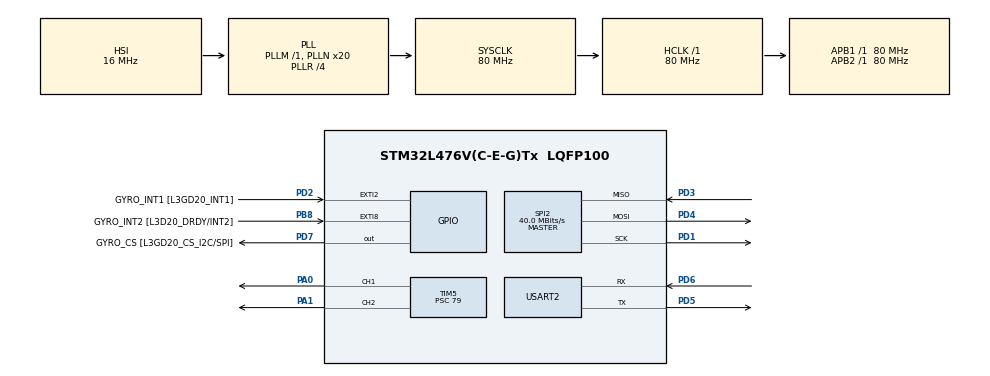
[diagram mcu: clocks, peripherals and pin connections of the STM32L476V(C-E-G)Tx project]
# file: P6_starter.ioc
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FREERTOS.Tasks01=defaultTask,0,128,StartDefaultTask,Default,NULL
FREERTOS.configTOTAL_HEAP_SIZE=10000
FREERTOS.configUSE_IDLE_HOOK=1
Mcu.Family=STM32L4
Mcu.Name=STM32L476V(C-E-G)Tx
Mcu.Package=LQFP100
NVIC.PriorityGroup=NVIC_PRIORITYGROUP_4
NVIC.TIM2_IRQn=true\:0\:0\:false\:false\:true\:false\:false
NVIC.TimeBase=TIM2_IRQn
NVIC.TimeBaseIP=TIM2
NVIC.USART2_IRQn=true\:5\:0\:false\:false\:true\:true\:true
PA0.GPIO_Speed=GPIO_SPEED_FREQ_HIGH
PA0.Signal=S_TIM5_CH1
PA1.GPIO_Speed=GPIO_SPEED_FREQ_HIGH
PA1.Signal=S_TIM5_CH2
PB8.GPIO_Label=GYRO_INT2 [L3D20_DRDY/INT2]
PB8.Signal=GPXTI8
PD1.Mode=Full_Duplex_Master
PD1.Signal=SPI2_SCK
PD2.GPIO_Label=GYRO_INT1 [L3GD20_INT1]
PD2.Signal=GPXTI2
PD3.Mode=Full_Duplex_Master
PD3.Signal=SPI2_MISO
PD4.Mode=Full_Duplex_Master
PD4.Signal=SPI2_MOSI
PD5.Mode=Asynchronous
PD5.Signal=USART2_TX
PD6.Mode=Asynchronous
PD6.Signal=USART2_RX
PD7.GPIO_Label=GYRO_CS [L3GD20_CS_I2C/SPI]
PD7.GPIO_Speed=GPIO_SPEED_FREQ_VERY_HIGH
PD7.Signal=GPIO_Output
ProjectManager.HeapSize=0x200
ProjectManager.StackSize=0x400
ProjectManager.TargetToolchain=MDK-ARM V5
RCC.ADCFreq_Value=96000000
RCC.AHBFreq_Value=80000000
RCC.APB1Freq_Value=80000000
RCC.APB1TimFreq_Value=80000000
RCC.APB2Freq_Value=80000000
RCC.APB2TimFreq_Value=80000000
RCC.CortexFreq_Value=80000000
RCC.HCLKFreq_Value=80000000
RCC.HSE_VALUE=8000000
RCC.HSI_VALUE=16000000
RCC.LSE_VALUE=32768
RCC.MSI_VALUE=4000000
RCC.PLLN=20
RCC.PLLR=RCC_PLLR_DIV4
RCC.PLLSAI1N=12
RCC.PLLSAI1Q=RCC_PLLQ_DIV4
RCC.PLLSourceVirtual=RCC_PLLSOURCE_HSI
RCC.SYSCLKFreq_VALUE=80000000
RCC.SYSCLKSource=RCC_SYSCLKSOURCE_PLLCLK
RCC.USBFreq_Value=48000000
RCC.VCOOutputFreq_Value=320000000
SH.S_TIM5_CH1.0=TIM5_CH1,PWM Generation1 CH1
SH.S_TIM5_CH2.0=TIM5_CH2,PWM Generation2 CH2
SPI2.CalculateBaudRate=40.0 MBits/s
SPI2.Direction=SPI_DIRECTION_2LINES
SPI2.Mode=SPI_MODE_MASTER
SPI2.VirtualType=VM_MASTER
TIM5.Channel-PWM\ Generation1\ CH1=TIM_CHANNEL_1
TIM5.Channel-PWM\ Generation2\ CH2=TIM_CHANNEL_2
TIM5.Period=20000
TIM5.Prescaler=79
TIM5.Pulse-PWM\ Generation1\ CH1=10000
TIM5.Pulse-PWM\ Generation2\ CH2=1000
USART2.VirtualMode-Asynchronous=VM_ASYNC
VP_FREERTOS_VS_ENABLE.Mode=Enabled
VP_RNG_VS_RNG.Mode=RNG_Activate
VP_SYS_VS_tim2.Mode=TIM2
VP_TIM5_VS_ClockSourceINT.Mode=Internal
board=custom

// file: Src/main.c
/* USER CODE BEGIN Header */
/**
  ******************************************************************************
  * @file           : main.c
  * @brief          : Main program body
  ******************************************************************************
  * This notice applies to any and all portions of this file
  * that are not between comment pairs USER CODE BEGIN and
  * USER CODE END. Other portions of this file, whether
  * inserted by the user or by software development tools
  * are owned by their respective copyright owners.
  *
  * Copyright (c) 2019 STMicroelectronics International N.V.
  * All rights reserved.
  *
  * Redistribution and use in source and binary forms, with or without
  * modification, are permitted, provided that the following conditions are met:
  *
  * 1. Redistribution of source code must retain the above copyright notice,
  *    this list of conditions and the following disclaimer.
  * 2. Redistributions in binary form must reproduce the above copyright notice,
  *    this list of conditions and the following disclaimer in the documentation
  *    and/or other materials provided with the distribution.
  * 3. Neither the name of STMicroelectronics nor the names of other
  *    contributors to this software may be used to endorse or promote products
  *    derived from this software without specific written permission.
  * 4. This software, including modifications and/or derivative works of this
  *    software, must execute solely and exclusively on microcontroller or
  *    microprocessor devices manufactured by or for STMicroelectronics.
  * 5. Redistribution and use of this software other than as permitted under
  *    this license is void and will automatically terminate your rights under
  *    this license.
  *
  * THIS SOFTWARE IS PROVIDED BY STMICROELECTRONICS AND CONTRIBUTORS "AS IS"
  * AND ANY EXPRESS, IMPLIED OR STATUTORY WARRANTIES, INCLUDING, BUT NOT
  * LIMITED TO, THE IMPLIED WARRANTIES OF MERCHANTABILITY, FITNESS FOR A
  * PARTICULAR PURPOSE AND NON-INFRINGEMENT OF THIRD PARTY INTELLECTUAL PROPERTY
  * RIGHTS ARE DISCLAIMED TO THE FULLEST EXTENT PERMITTED BY LAW. IN NO EVENT
  * SHALL STMICROELECTRONICS OR CONTRIBUTORS BE LIABLE FOR ANY DIRECT, INDIRECT,
  * INCIDENTAL, SPECIAL, EXEMPLARY, OR CONSEQUENTIAL DAMAGES (INCLUDING, BUT NOT
  * LIMITED TO, PROCUREMENT OF SUBSTITUTE GOODS OR SERVICES; LOSS OF USE, DATA,
  * OR PROFITS; OR BUSINESS INTERRUPTION) HOWEVER CAUSED AND ON ANY THEORY OF
  * LIABILITY, WHETHER IN CONTRACT, STRICT LIABILITY, OR TORT (INCLUDING
  * NEGLIGENCE OR OTHERWISE) ARISING IN ANY WAY OUT OF THE USE OF THIS SOFTWARE,
  * EVEN IF ADVISED OF THE POSSIBILITY OF SUCH DAMAGE.
  *
  ******************************************************************************
  */
/* USER CODE END Header */

#include "main.h"
#include "cmsis_os.h"
#include "rng.h"
#include "spi.h"
#include "tim.h"
#include "usart.h"
#include "gpio.h"
#include "servo.h"
#include "Timer.h"
#include "GPIOINP.h"

/* USER CODE BEGIN Includes */
#include "stdio.h"
#include "string.h"
/* USER CODE END Includes */

void SystemClock_Config(void);
void MX_FREERTOS_Init(void);

int main(void)
{

  /* MCU Configuration--------------------------------------------------------*/

  /* Reset of all peripherals, Initializes the Flash interface and the Systick. */
  HAL_Init();

  /* Configure the system clock */
  SystemClock_Config();

  /* Initialize all configured peripherals */
  MX_GPIO_Init();
  MX_USART2_UART_Init();
  MX_RNG_Init();
  MX_TIM5_Init();
  MX_SPI2_Init();
  initTIM2();
  initTIM3();
  initGPIOA();

  /* USER CODE BEGIN 2 */

  gyro_task_init();
  servo_task_init(0, "SERVO_TASK");
  player_servo_task_init(1, "PLAYER_SERVO_TASK");

  /* USER CODE END 2 */

  /* Call init function for freertos objects (in freertos.c) */
  MX_FREERTOS_Init();

  /* Start scheduler */
  osKernelStart();

  /* We should never get here as control is now taken by the scheduler */

  /* Infinite loop */
  while (1)
  {

  }
}

void SystemClock_Config(void)
{
  RCC_OscInitTypeDef RCC_OscInitStruct = {0};
  RCC_ClkInitTypeDef RCC_ClkInitStruct = {0};
  RCC_PeriphCLKInitTypeDef PeriphClkInit = {0};

  /**Initializes the CPU, AHB and APB busses clocks
  */
  RCC_OscInitStruct.OscillatorType = RCC_OSCILLATORTYPE_HSI;
  RCC_OscInitStruct.HSIState = RCC_HSI_ON;
  RCC_OscInitStruct.HSICalibrationValue = RCC_HSICALIBRATION_DEFAULT;
  RCC_OscInitStruct.PLL.PLLState = RCC_PLL_ON;
  RCC_OscInitStruct.PLL.PLLSource = RCC_PLLSOURCE_HSI;
  RCC_OscInitStruct.PLL.PLLM = 1;
  RCC_OscInitStruct.PLL.PLLN = 20;
  RCC_OscInitStruct.PLL.PLLP = RCC_PLLP_DIV7;
  RCC_OscInitStruct.PLL.PLLQ = RCC_PLLQ_DIV2;
  RCC_OscInitStruct.PLL.PLLR = RCC_PLLR_DIV4;
  if (HAL_RCC_OscConfig(&RCC_OscInitStruct) != HAL_OK)
  {
    Error_Handler();
  }
  /**Initializes the CPU, AHB and APB busses clocks
  */
  RCC_ClkInitStruct.ClockType = RCC_CLOCKTYPE_HCLK|RCC_CLOCKTYPE_SYSCLK
                              |RCC_CLOCKTYPE_PCLK1|RCC_CLOCKTYPE_PCLK2;
  RCC_ClkInitStruct.SYSCLKSource = RCC_SYSCLKSOURCE_PLLCLK;
  RCC_ClkInitStruct.AHBCLKDivider = RCC_SYSCLK_DIV1;
  RCC_ClkInitStruct.APB1CLKDivider = RCC_HCLK_DIV1;
  RCC_ClkInitStruct.APB2CLKDivider = RCC_HCLK_DIV1;

  if (HAL_RCC_ClockConfig(&RCC_ClkInitStruct, FLASH_LATENCY_4) != HAL_OK)
  {
    Error_Handler();
  }
  PeriphClkInit.PeriphClockSelection = RCC_PERIPHCLK_USART2|RCC_PERIPHCLK_RNG;
  PeriphClkInit.Usart2ClockSelection = RCC_USART2CLKSOURCE_PCLK1;
  PeriphClkInit.RngClockSelection = RCC_RNGCLKSOURCE_PLLSAI1;
  PeriphClkInit.PLLSAI1.PLLSAI1Source = RCC_PLLSOURCE_HSI;
  PeriphClkInit.PLLSAI1.PLLSAI1M = 1;
  PeriphClkInit.PLLSAI1.PLLSAI1N = 12;
  PeriphClkInit.PLLSAI1.PLLSAI1P = RCC_PLLP_DIV7;
  PeriphClkInit.PLLSAI1.PLLSAI1Q = RCC_PLLQ_DIV4;
  PeriphClkInit.PLLSAI1.PLLSAI1R = RCC_PLLR_DIV2;
  PeriphClkInit.PLLSAI1.PLLSAI1ClockOut = RCC_PLLSAI1_48M2CLK;
  if (HAL_RCCEx_PeriphCLKConfig(&PeriphClkInit) != HAL_OK)
  {
    Error_Handler();
  }
  /**Configure the main internal regulator output voltage
  */
  if (HAL_PWREx_ControlVoltageScaling(PWR_REGULATOR_VOLTAGE_SCALE1) != HAL_OK)
  {
    Error_Handler();
  }
}

void HAL_TIM_PeriodElapsedCallback(TIM_HandleTypeDef *htim)
{
  if (htim->Instance == TIM2) {
    HAL_IncTick();
  }
}

void Error_Handler(void)
{
}

/************************ (C) COPYRIGHT STMicroelectronics *****END OF FILE****/

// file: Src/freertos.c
/* USER CODE BEGIN Header */
/**
  ******************************************************************************
  * File Name          : freertos.c
  * Description        : Code for freertos applications
  ******************************************************************************
  * This notice applies to any and all portions of this file
  * that are not between comment pairs USER CODE BEGIN and
  * USER CODE END. Other portions of this file, whether
  * inserted by the user or by software development tools
  * are owned by their respective copyright owners.
  *
  * Copyright (c) 2019 STMicroelectronics International N.V.
  * All rights reserved.
  *
  * Redistribution and use in source and binary forms, with or without
  * modification, are permitted, provided that the following conditions are met:
  *
  * 1. Redistribution of source code must retain the above copyright notice,
  *    this list of conditions and the following disclaimer.
  * 2. Redistributions in binary form must reproduce the above copyright notice,
  *    this list of conditions and the following disclaimer in the documentation
  *    and/or other materials provided with the distribution.
  * 3. Neither the name of STMicroelectronics nor the names of other
  *    contributors to this software may be used to endorse or promote products
  *    derived from this software without specific written permission.
  * 4. This software, including modifications and/or derivative works of this
  *    software, must execute solely and exclusively on microcontroller or
  *    microprocessor devices manufactured by or for STMicroelectronics.
  * 5. Redistribution and use of this software other than as permitted under
  *    this license is void and will automatically terminate your rights under
  *    this license.
  *
  * THIS SOFTWARE IS PROVIDED BY STMICROELECTRONICS AND CONTRIBUTORS "AS IS"
  * AND ANY EXPRESS, IMPLIED OR STATUTORY WARRANTIES, INCLUDING, BUT NOT
  * LIMITED TO, THE IMPLIED WARRANTIES OF MERCHANTABILITY, FITNESS FOR A
  * PARTICULAR PURPOSE AND NON-INFRINGEMENT OF THIRD PARTY INTELLECTUAL PROPERTY
  * RIGHTS ARE DISCLAIMED TO THE FULLEST EXTENT PERMITTED BY LAW. IN NO EVENT
  * SHALL STMICROELECTRONICS OR CONTRIBUTORS BE LIABLE FOR ANY DIRECT, INDIRECT,
  * INCIDENTAL, SPECIAL, EXEMPLARY, OR CONSEQUENTIAL DAMAGES (INCLUDING, BUT NOT
  * LIMITED TO, PROCUREMENT OF SUBSTITUTE GOODS OR SERVICES; LOSS OF USE, DATA,
  * OR PROFITS; OR BUSINESS INTERRUPTION) HOWEVER CAUSED AND ON ANY THEORY OF
  * LIABILITY, WHETHER IN CONTRACT, STRICT LIABILITY, OR TORT (INCLUDING
  * NEGLIGENCE OR OTHERWISE) ARISING IN ANY WAY OUT OF THE USE OF THIS SOFTWARE,
  * EVEN IF ADVISED OF THE POSSIBILITY OF SUCH DAMAGE.
  *
  ******************************************************************************
  */
/* USER CODE END Header */

#include "FreeRTOS.h"
#include "task.h"
#include "main.h"
#include "cmsis_os.h"

osThreadId defaultTaskHandle;

void StartDefaultTask(void const * argument);

void MX_FREERTOS_Init(void); /* (MISRA C 2004 rule 8.1) */

/* Hook prototypes */
void vApplicationIdleHook(void);

/* USER CODE BEGIN 2 */
__weak void vApplicationIdleHook( void )
{
   /* vApplicationIdleHook() will only be called if configUSE_IDLE_HOOK is set
   to 1 in FreeRTOSConfig.h. It will be called on each iteration of the idle
   task. It is essential that code added to this hook function never attempts
   to block in any way (for example, call xQueueReceive() with a block time
   specified, or call vTaskDelay()). If the application makes use of the
   vTaskDelete() API function (as this demo application does) then it is also
   important that vApplicationIdleHook() is permitted to return to its calling
   function, because it is the responsibility of the idle task to clean up
   memory allocated by the kernel to any task that has since been deleted. */
}
/* USER CODE END 2 */

void MX_FREERTOS_Init(void) {

  /* Create the thread(s) */
  /* definition and creation of defaultTask */
  osThreadDef(defaultTask, StartDefaultTask, osPriorityNormal, 0, 128);
  defaultTaskHandle = osThreadCreate(osThread(defaultTask), NULL);

}

void StartDefaultTask(void const * argument)
{

  for(;;)
  {
    osDelay(1);
  }
}

/************************ (C) COPYRIGHT STMicroelectronics *****END OF FILE****/
